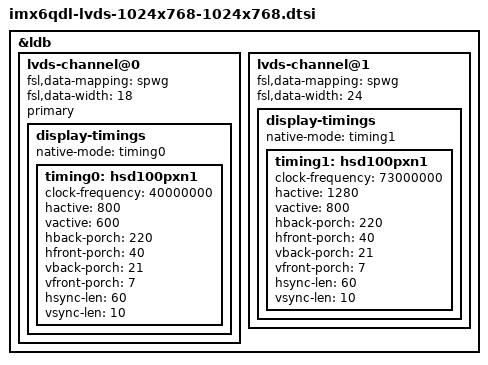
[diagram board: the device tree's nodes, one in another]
&ldb {
	status = "okay";

	lvds-channel@0 {
		fsl,data-mapping = "spwg";
        fsl,data-width = <18>;
		primary;
		status = "okay";

		display-timings {
			native-mode = <&timing0>;
			timing0: hsd100pxn1 {
				clock-frequency = <40000000>;
                hactive = <800>;
                vactive = <600>;
				hback-porch = <220>;
				hfront-porch = <40>;
				vback-porch = <21>;
				vfront-porch = <7>;
				hsync-len = <60>;
				vsync-len = <10>;
			};
		};
	};

	lvds-channel@1 {
		fsl,data-mapping = "spwg";
		fsl,data-width = <24>;
		status = "okay";

		display-timings {
			native-mode = <&timing1>;
			timing1: hsd100pxn1 {
                clock-frequency = <73000000>;
                hactive = <1280>;
                vactive = <800>;
				hback-porch = <220>;
				hfront-porch = <40>;
				vback-porch = <21>;
				vfront-porch = <7>;
				hsync-len = <60>;
				vsync-len = <10>;
			};
		};
	};
};
